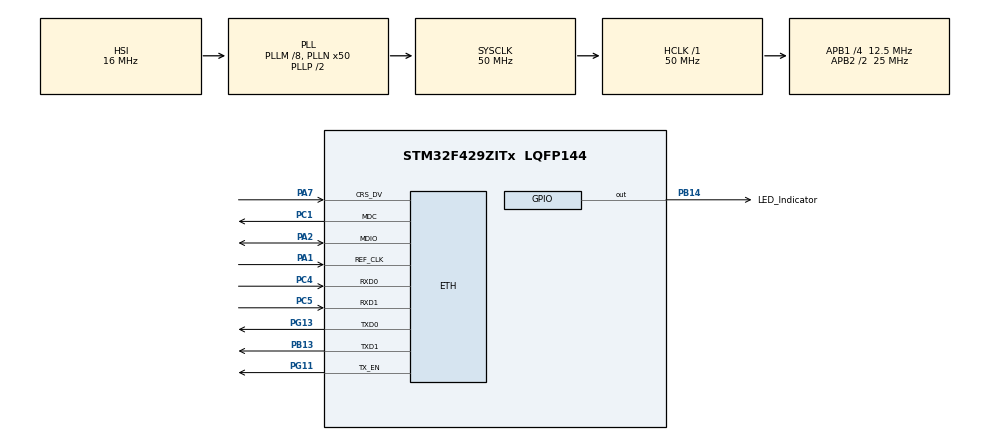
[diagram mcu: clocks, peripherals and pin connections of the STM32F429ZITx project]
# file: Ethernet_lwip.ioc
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ETH.MediaInterface=ETH_MEDIA_INTERFACE_RMII
ETH.PHY_Name_RMII=DP83848_PHY_ADDRESS
ETH.PHY_RESET=0x8000
ETH.PHY_SR=0x19
ETH.PhyAddress=0
FREERTOS.Tasks01=defaultTask,0,128,StartDefaultTask,Default,NULL,Dynamic,NULL,NULL;LED_Blink_Task,-3,128,StartBlinkTask,Default,NULL,Dynamic,NULL,NULL
LWIP.IP_ADDRESS=192.168.000.098
LWIP.LWIP_DHCP=1
LWIP.Version=v2.0.3_Cube
Mcu.Family=STM32F4
Mcu.Name=STM32F429ZITx
Mcu.Package=LQFP144
NVIC.ETH_IRQn=true\:5\:0\:false\:false\:true\:true\:false\:true
NVIC.PriorityGroup=NVIC_PRIORITYGROUP_4
NVIC.TIM1_UP_TIM10_IRQn=true\:0\:0\:false\:false\:true\:false\:false\:true
NVIC.TimeBase=TIM1_UP_TIM10_IRQn
NVIC.TimeBaseIP=TIM1
PA1.Mode=RMII
PA1.Signal=ETH_REF_CLK
PA2.Mode=RMII
PA2.Signal=ETH_MDIO
PA7.Mode=RMII
PA7.Signal=ETH_CRS_DV
PB13.Mode=RMII
PB13.Signal=ETH_TXD1
PB14.GPIO_Label=LED_Indicator
PB14.Signal=GPIO_Output
PC1.Mode=RMII
PC1.Signal=ETH_MDC
PC4.Mode=RMII
PC4.Signal=ETH_RXD0
PC5.Mode=RMII
PC5.Signal=ETH_RXD1
PG11.Mode=RMII
PG11.Signal=ETH_TX_EN
PG13.Mode=RMII
PG13.Signal=ETH_TXD0
ProjectManager.HeapSize=0x500
ProjectManager.StackSize=0x1000
ProjectManager.TargetToolchain=TrueSTUDIO
RCC.48MHZClocksFreq_Value=25000000
RCC.AHBFreq_Value=50000000
RCC.APB1CLKDivider=RCC_HCLK_DIV4
RCC.APB1Freq_Value=12500000
RCC.APB1TimFreq_Value=25000000
RCC.APB2CLKDivider=RCC_HCLK_DIV2
RCC.APB2Freq_Value=25000000
RCC.APB2TimFreq_Value=50000000
RCC.CortexFreq_Value=50000000
RCC.HCLKFreq_Value=50000000
RCC.HSE_VALUE=25000000
RCC.HSI_VALUE=16000000
RCC.LSE_VALUE=32768
RCC.PLLM=8
RCC.PLLN=50
RCC.SYSCLKFreq_VALUE=50000000
RCC.SYSCLKSource=RCC_SYSCLKSOURCE_PLLCLK
RCC.VCOOutputFreq_Value=100000000
VP_FREERTOS_VS_CMSIS_V1.Mode=CMSIS_V1
VP_LWIP_VS_Enabled.Mode=Enabled
VP_SYS_VS_tim1.Mode=TIM1
board=custom

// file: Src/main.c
/* USER CODE BEGIN Header */
/**
  ******************************************************************************
  * @file           : main.c
  * @brief          : Main program body
  ******************************************************************************
  * @attention
  *
  * <h2><center>&copy; Copyright (c) 2019 STMicroelectronics.
  * All rights reserved.</center></h2>
  *
  * This software component is licensed by ST under BSD 3-Clause license,
  * the "License"; You may not use this file except in compliance with the
  * License. You may obtain a copy of the License at:
  *                        opensource.org/licenses/BSD-3-Clause
  *
  ******************************************************************************
  */
/* USER CODE END Header */

#include "main.h"
#include "cmsis_os.h"
#include "lwip.h"
#include "gpio.h"

void SystemClock_Config(void);
void MX_FREERTOS_Init(void);

int main(void)
{

  /* MCU Configuration--------------------------------------------------------*/

  /* Reset of all peripherals, Initializes the Flash interface and the Systick. */
  HAL_Init();

  /* Configure the system clock */
  SystemClock_Config();

  /* Initialize all configured peripherals */
  MX_GPIO_Init();

  /* Call init function for freertos objects (in freertos.c) */
  MX_FREERTOS_Init();

  /* Start scheduler */
  osKernelStart();

  /* We should never get here as control is now taken by the scheduler */

  /* Infinite loop */
  while (1)
  {

  }
}

void SystemClock_Config(void)
{
  RCC_OscInitTypeDef RCC_OscInitStruct = {0};
  RCC_ClkInitTypeDef RCC_ClkInitStruct = {0};

  /** Configure the main internal regulator output voltage
  */
  __HAL_RCC_PWR_CLK_ENABLE();
  __HAL_PWR_VOLTAGESCALING_CONFIG(PWR_REGULATOR_VOLTAGE_SCALE3);
  /** Initializes the CPU, AHB and APB busses clocks
  */
  RCC_OscInitStruct.OscillatorType = RCC_OSCILLATORTYPE_HSI;
  RCC_OscInitStruct.HSIState = RCC_HSI_ON;
  RCC_OscInitStruct.HSICalibrationValue = RCC_HSICALIBRATION_DEFAULT;
  RCC_OscInitStruct.PLL.PLLState = RCC_PLL_ON;
  RCC_OscInitStruct.PLL.PLLSource = RCC_PLLSOURCE_HSI;
  RCC_OscInitStruct.PLL.PLLM = 8;
  RCC_OscInitStruct.PLL.PLLN = 50;
  RCC_OscInitStruct.PLL.PLLP = RCC_PLLP_DIV2;
  RCC_OscInitStruct.PLL.PLLQ = 4;
  if (HAL_RCC_OscConfig(&RCC_OscInitStruct) != HAL_OK)
  {
    Error_Handler();
  }
  /** Initializes the CPU, AHB and APB busses clocks
  */
  RCC_ClkInitStruct.ClockType = RCC_CLOCKTYPE_HCLK|RCC_CLOCKTYPE_SYSCLK
                              |RCC_CLOCKTYPE_PCLK1|RCC_CLOCKTYPE_PCLK2;
  RCC_ClkInitStruct.SYSCLKSource = RCC_SYSCLKSOURCE_PLLCLK;
  RCC_ClkInitStruct.AHBCLKDivider = RCC_SYSCLK_DIV1;
  RCC_ClkInitStruct.APB1CLKDivider = RCC_HCLK_DIV4;
  RCC_ClkInitStruct.APB2CLKDivider = RCC_HCLK_DIV2;

  if (HAL_RCC_ClockConfig(&RCC_ClkInitStruct, FLASH_LATENCY_1) != HAL_OK)
  {
    Error_Handler();
  }
}

void HAL_TIM_PeriodElapsedCallback(TIM_HandleTypeDef *htim)
{
  if (htim->Instance == TIM1) {
    HAL_IncTick();
  }
}

void Error_Handler(void)
{
}

/************************ (C) COPYRIGHT STMicroelectronics *****END OF FILE****/

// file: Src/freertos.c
/* USER CODE BEGIN Header */
/**
  ******************************************************************************
  * File Name          : freertos.c
  * Description        : Code for freertos applications
  ******************************************************************************
  * @attention
  *
  * <h2><center>&copy; Copyright (c) 2019 STMicroelectronics.
  * All rights reserved.</center></h2>
  *
  * This software component is licensed by ST under Ultimate Liberty license
  * SLA0044, the "License"; You may not use this file except in compliance with
  * the License. You may obtain a copy of the License at:
  *                             www.st.com/SLA0044
  *
  ******************************************************************************
  */
/* USER CODE END Header */

#include "FreeRTOS.h"
#include "task.h"
#include "main.h"
#include "cmsis_os.h"

/* USER CODE BEGIN Includes */

#include "api.h"

/* USER CODE END Includes */

osThreadId defaultTaskHandle;
osThreadId LED_Blink_TaskHandle;

void StartDefaultTask(void const * argument);
void StartBlinkTask(void const * argument);

extern void MX_LWIP_Init(void);
void MX_FREERTOS_Init(void); /* (MISRA C 2004 rule 8.1) */

void MX_FREERTOS_Init(void) {

  /* Create the thread(s) */
  /* definition and creation of defaultTask */
  osThreadDef(defaultTask, StartDefaultTask, osPriorityNormal, 0, 128);
  defaultTaskHandle = osThreadCreate(osThread(defaultTask), NULL);

  /* definition and creation of LED_Blink_Task */
  osThreadDef(LED_Blink_Task, StartBlinkTask, osPriorityIdle, 0, 128);
  LED_Blink_TaskHandle = osThreadCreate(osThread(LED_Blink_Task), NULL);

}

const static char indexdata[] =
		"<html> \
		<head><title>A test page</title></head> \
		<body> \This is a small test page. By Justin\</body> \
		</html>";

const static char http_html_hdr[] ="Content-type: text/html\r\n\r\n";

static void tcpecho_thread(void *arg){
	err_t err;
	err_t accept_err;
	err_t recv_err;

	struct netconn *conn, *newconn;
	struct netbuf *buf;
	char *rq;
	uint16_t len;

	//create new connection identifier
	conn = netconn_new(NETCONN_TCP);

	if(conn!=NULL){

		//Bind connection to port 80
		err = netconn_bind(conn, NULL, 80);

		if(err == ERR_OK){
			//Tell connection to go into listening mode
			netconn_listen(conn);

			while(1){
				//Grab new connection
				accept_err = netconn_accept(conn, &newconn);

				//Process new connection
				if(accept_err == ERR_OK){
					while((recv_err = netconn_recv(newconn, &buf)) == ERR_OK){
						do
						{
							netbuf_data(buf, &rq, &len);
							//netconn_write(newconn, data, len, NETCONN_COPY);

							/* Check if the request was an HTTP "GET /\r\n". */
							if(rq[0] == 'G' && rq[1] == 'E' &&rq[2] == 'T' && rq[3] == ' ' &&rq[4] == '/') {

								/* Send the header. */
								//netconn_write(newconn, http_html_hdr, sizeof(http_html_hdr),NETCONN_NOCOPY);

								/* Send the actual web page. */
								netconn_write(newconn, indexdata, sizeof(indexdata),NETCONN_NOCOPY);

								/* Close the connection. */
								netconn_close(newconn);
							}

						}
						while(netbuf_next(buf) >= 0);

						netbuf_delete(buf);
					}
					netconn_close(newconn);
					netconn_delete(newconn);
				}
			}
		}
		else {
			netconn_delete(newconn);
		}
	}
}

void StartDefaultTask(void const * argument)
{
  /* init code for LWIP */
  MX_LWIP_Init();

  //tcpip_init(NULL, NULL);

  //Netif_Config();

  int TCPECHO_THREAD_PRIO = 60;
  sys_thread_new("tcpecho_thread", tcpecho_thread, NULL, DEFAULT_THREAD_STACKSIZE, TCPECHO_THREAD_PRIO);

  for(;;)
  {
    osDelay(1);
  }
}

void StartBlinkTask(void const * argument)
{
  /* USER CODE BEGIN StartBlinkTask */
  /* Infinite loop */
  for(;;)
  {
	  HAL_GPIO_WritePin(LED_Indicator_GPIO_Port, LED_Indicator_Pin, GPIO_PIN_RESET);
	  osDelay(1000);
	  HAL_GPIO_WritePin(LED_Indicator_GPIO_Port, LED_Indicator_Pin, GPIO_PIN_SET);
	  osDelay(1000);
  }
  /* USER CODE END StartBlinkTask */
}

/************************ (C) COPYRIGHT STMicroelectronics *****END OF FILE****/
